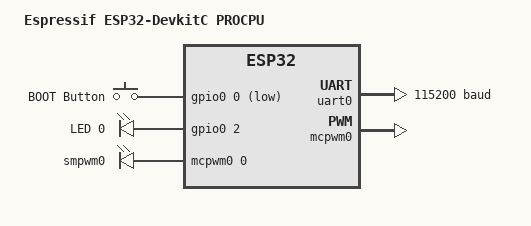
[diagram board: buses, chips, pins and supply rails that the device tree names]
/*
 * Copyright (c) 2023 Espressif Systems (Shanghai) Co., Ltd.
 *
 * SPDX-License-Identifier: Apache-2.0
 */
/dts-v1/;

#include <espressif/esp32/esp32_wroom_32ue_n4.dtsi>
#include "my_esp32_devkitc_wroom-pinctrl.dtsi"
#include <zephyr/dt-bindings/input/input-event-codes.h>
#include <espressif/partitions_0x1000_amp.dtsi>

/ {
	model = "Espressif ESP32-DevkitC PROCPU";
	compatible = "espressif,esp32";

	aliases {
		uart-0 = &uart0;
		i2c-0 = &i2c0;
		sw0 = &button0;
		watchdog0 = &wdt0;
		led0 = &led0;
		pwm0 = &smpwm0;
	};

	buttons {
		compatible = "gpio-keys";
		button0: button_0 {
			gpios = <&gpio0 0 (GPIO_PULL_UP | GPIO_ACTIVE_LOW)>;
			label = "BOOT Button";
			zephyr,code = <INPUT_KEY_0>;
		};
	};

	leds {
		compatible = "gpio-leds";
		led0: led_0 {
			gpios = <&gpio0 2 GPIO_ACTIVE_HIGH>;
			label = "LED 0";
		};
	};

	servomotor {
		compatible = "pwm-leds";
		smpwm0: smpwm_0 {
			pwms = <&mcpwm0 0 20000 PWM_POLARITY_NORMAL>; //Channel 0 -> Output PWM0A
		};
	};

	chosen {
		zephyr,sram = &sram1;
		zephyr,console = &uart0;
		zephyr,shell-uart = &uart0;
		zephyr,flash = &flash0;
		zephyr,code-partition = &slot0_partition;
	};
};

&uart0 {
	status = "okay";
	current-speed = <115200>;
	pinctrl-0 = <&uart0_default>;
	pinctrl-names = "default";
};

&gpio0 {
	status = "okay";
};

&gpio1 {
	status = "okay";
};

&mcpwm0 {
	pinctrl-0 = <&mcpwm0_default>;
	pinctrl-names = "default";
	prescale = <255>;
	prescale-timer0 = <50>;
	prescale-timer1 = <103>;
	prescale-timer2 = <255>;
	status = "okay";
};
